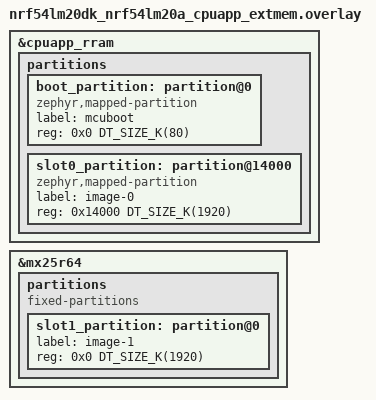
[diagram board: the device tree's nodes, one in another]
/*
 * Copyright (c) 2026 Nordic Semiconductor ASA
 *
 * SPDX-License-Identifier: LicenseRef-Nordic-5-Clause
 */

/delete-node/ &boot_partition;
/delete-node/ &slot0_partition;
/delete-node/ &slot1_partition;

&cpuapp_rram {
	partitions {
		boot_partition: partition@0 {
			compatible = "zephyr,mapped-partition";
			label = "mcuboot";
			reg = <0x0 DT_SIZE_K(80)>;
		};

		slot0_partition: partition@14000 {
			compatible = "zephyr,mapped-partition";
			label = "image-0";
			reg = <0x14000 DT_SIZE_K(1920)>;
		};
	};
};

&mx25r64 {
	status = "okay";

	partitions {
		compatible = "fixed-partitions";
		#address-cells = <1>;
		#size-cells = <1>;

		slot1_partition: partition@0 {
			label = "image-1";
			reg = <0x0 DT_SIZE_K(1920)>;
		};
	};
};
